# haltium_application register map
Vendor: Nordic Semiconductor; Series: nRFHaltium; File version: 1
CPU: CM33 r0p4, little endian, MPU, FPU, 3 interrupt priority bits, 480 interrupts
Registers are 32-bit, read-write, reset 0x0 unless marked. A register's access mark holds for its fields unless they carry their own. Offsets are from the block's base; [hi:lo] are bit positions; {n}, {i} and the like mark numbered series.

## GLOBAL_P0_NS — GPIO Port 0
Base 0x4F938000
Same registers: GLOBAL_P{n}_NS {0x4F938000+0x200*n} (n=1..14), GLOBAL_P15_NS 0x4F939E00 (alternate view of GLOBAL_GGPIOINTERNAL_NS), GLOBAL_P{n}_S {0x5F938000+0x200*n} (n=0..14), GLOBAL_P15_S 0x5F939E00 (alternate view of GLOBAL_GGPIOINTERNAL_S)
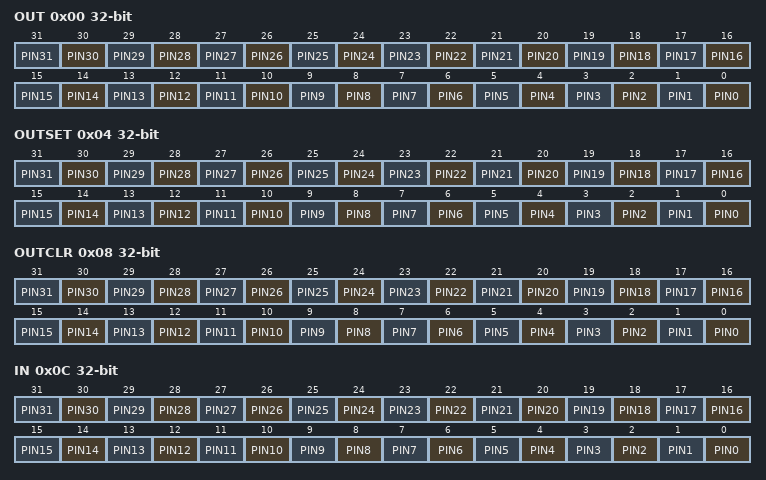
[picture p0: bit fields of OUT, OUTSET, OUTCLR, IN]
0x00 OUT — Write GPIO port
  [all] fields
    0=Low (Pin driver is low); 1=High (Pin driver is high)
  [n] PIN{n} (n=0..31)
0x04 OUTSET write-1-sets — Set individual bits in GPIO port
  [all] fields
    on read: 0=Low (Read: pin driver is low); 1=High (Read: pin driver is high) | on write: 1=Set (Write: writing a '1' sets the pin high; writing a '0' has no effect)
  [n] PIN{n} (n=0..31)
0x08 OUTCLR write-1-clears — Clear individual bits in GPIO port
  [all] fields
    on read: 0=Low (Read: pin driver is low); 1=High (Read: pin driver is high) | on write: 1=Clear (Write: writing a '1' sets the pin low; writing a '0' has no effect)
  [n] PIN{n} (n=0..31)
0x0C IN ro — Read GPIO port
  [all] fields
    0=Low (Pin input is low); 1=High (Pin input is high)
  [n] PIN{n} (n=0..31)
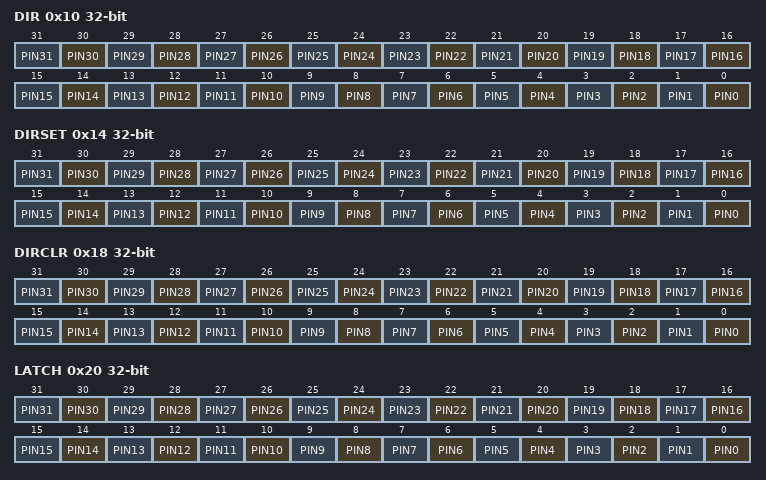
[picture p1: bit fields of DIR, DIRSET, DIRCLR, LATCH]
0x10 DIR — Direction of GPIO pins
  [all] fields
    0=Input (Pin set as input); 1=Output (Pin set as output)
  [n] PIN{n} (n=0..31)
0x14 DIRSET write-1-sets
  [all] fields
    on read: 0=Input (Read: pin set as input); 1=Output (Read: pin set as output) | on write: 1=Set (Write: writing a '1' sets pin to output; writing a '0' has no effect)
  [n] PIN{n} (n=0..31) — Set as output pin {n}
0x18 DIRCLR write-1-clears — DIR clear register
  [all] fields
    on read: 0=Input (Read: pin set as input); 1=Output (Read: pin set as output) | on write: 1=Clear (Write: writing a '1' sets pin to input; writing a '0' has no effect)
  [n] PIN{n} (n=0..31) — Set as input pin {n}
0x20 LATCH — Latch register indicating what GPIO pins that have met the criteria set in the PINCNF[n].SENSE registers
  [all] fields
    0=NotLatched (Criteria has not been met); 1=Latched (Criteria has been met)
  [n] PIN{n} (n=0..31) — Status on whether PIN{n} has met criteria set in PINCNF[{n}].SENSE register. Write '1' to clear.
0x24 DETECTMODE — Select between default DETECT signal behavior and LDETECT mode
  [0] DETECTMODE
    0=Default (DETECT directly connected to PIN DETECT signals); 1=LDETECT (Use the latched LDETECT behavior)
0x28 RETAIN — Enable retention for those GPIO registers marked as retained
  [0] ENABLE — Enable retention
    0=Disabled (Retention disabled); 1=Enabled (Retention enabled)
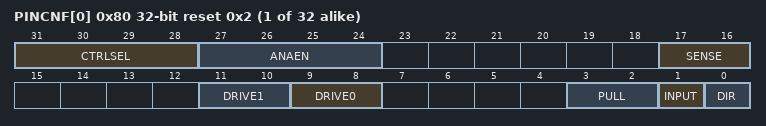
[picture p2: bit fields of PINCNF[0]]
{0x80+4i} PINCNF[{i}] (i=0..31) reset 0x2 — Description collection: Pin n configuration of GPIO pin
  [31:28] CTRLSEL — Select which MCU/Subsystem controls this pin
    0=GPIO (GPIO peripheral); 1=VPR (VPR processor); 1=GRC (GRC system); 2=RadioCore; 2=SecureDomain; 2=PWM (PWM peripheral); 2=I3C (I3C peripheral); 3=Serial (SPIM/SPIS/TWIM/TWIS/UARTE peripheral); 3=HSSPI (High-speed SPI peripheral); 4=EXMIF (EXMIF peripheral); 7=TND (Trace and Debug Subsystem)
  [27:24] ANAEN — Override of analog mux enable signals for pads with analog functionality
    0=Disabled (Override of analog mux is disabled); {v}=AE{v-1} (Enable analog signal {v-1} (analog test bus)) (v=1..6)
  [17:16] SENSE — Pin sensing mechanism
    0=Disabled; 2=High (Sense for high level); 3=Low (Sense for low level)
  [11:10] DRIVE1 — Drive configuration for '1'
    0=S1 (Standard '1'); 1=H1 (High drive '1'); 2=D1 (Disconnect '1'(normally used for wired-or connections)); 3=E1 (Extra high drive '1')
  [9:8] DRIVE0 — Drive configuration for '0'
    0=S0 (Standard '0'); 1=H0 (High drive '0'); 2=D0 (Disconnect '0'(normally used for wired-or connections)); 3=E0 (Extra high drive '0')
  [3:2] PULL — Pull configuration
    0=Disabled (No pull); 1=Pull down on pin; 3=Pull up on pin
  [1] INPUT — Connect or disconnect input buffer
    0=Connect input buffer; 1=Disconnect input buffer
  [0] DIR — Pin direction. Same physical register as DIR register
    0=Input (Configure pin as an input pin); 1=Output (Configure pin as an output pin)
